VERSION "created by canmatrix"

NS_ :

BS_:

BU_: IMU_X IMU_Y IMU_Z

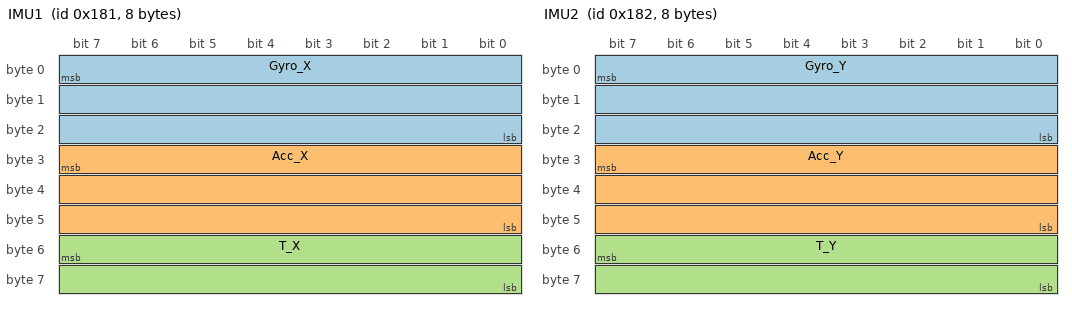
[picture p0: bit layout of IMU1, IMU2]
BO_ 385 IMU1: 8 IMU_X
 SG_ Gyro_X : 7|24@0- (0.001,0) [0|0] "deg/s" Vector__XXX
 SG_ Acc_X : 31|24@0- (0.00001,0) [0|0] "g" Vector__XXX
 SG_ T_X : 55|16@0- (0.01,0) [0|0] "C" Vector__XXX

BO_ 386 IMU2: 8 IMU_Y
 SG_ Gyro_Y : 7|24@0- (0.001,0) [0|0] "deg/s" Vector__XXX
 SG_ Acc_Y : 31|24@0- (0.00001,0) [0|0] "g" Vector__XXX
 SG_ T_Y : 55|16@0- (0.01,0) [0|0] "C" Vector__XXX

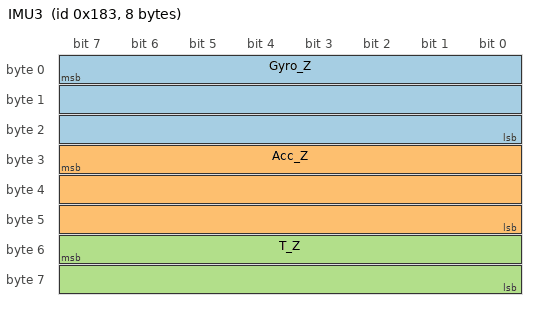
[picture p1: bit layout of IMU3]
BO_ 387 IMU3: 8 IMU_Z
 SG_ Gyro_Z : 7|24@0- (0.001,0) [0|0] "deg/s" Vector__XXX
 SG_ Acc_Z : 31|24@0- (0.00001,0) [0|0] "g" Vector__XXX
 SG_ T_Z : 55|16@0- (0.01,0) [0|0] "C" Vector__XXX
